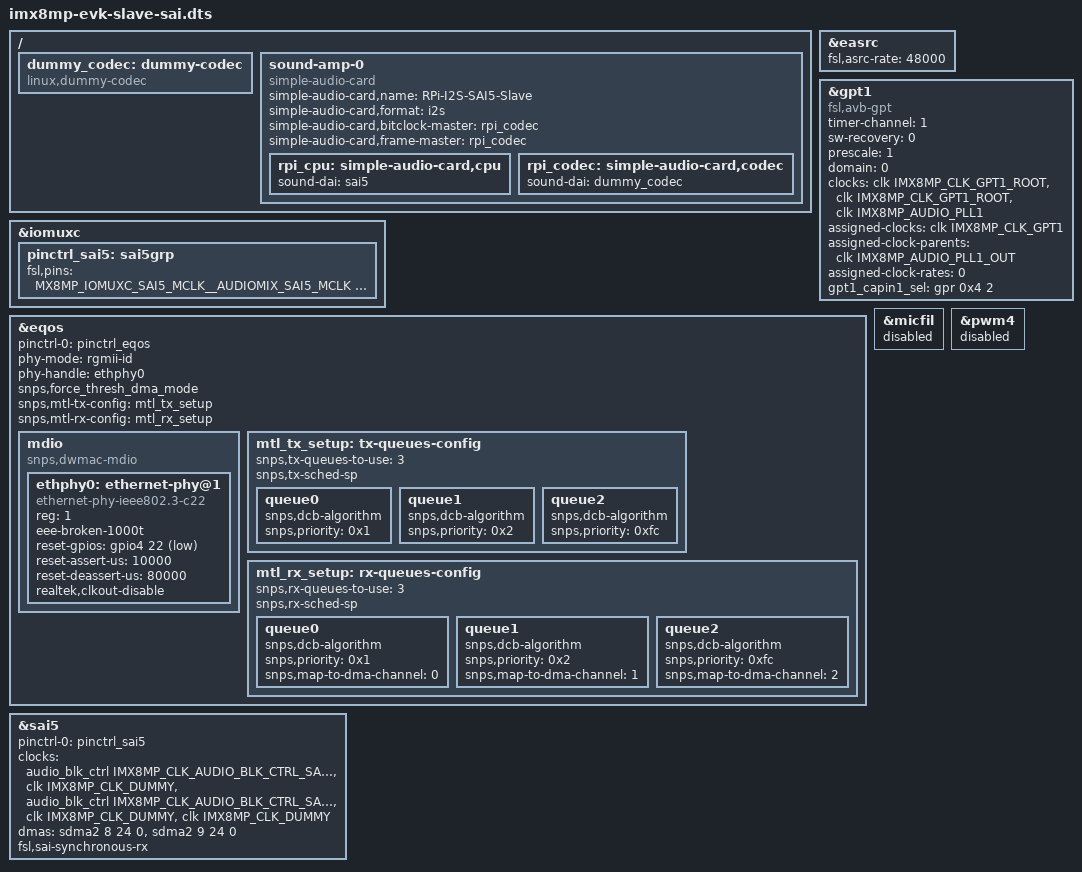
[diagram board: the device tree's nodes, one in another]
// SPDX-License-Identifier: (GPL-2.0+ OR MIT)
/*
 * Copyright 2021 NXP
 */

/dts-v1/;

#include "imx8mp-evk.dts"

/* Enable easrc */
&easrc {
	fsl,asrc-rate  = <48000>;
	status = "okay";
};

/* AVB HW timer*/
&gpt1 {
	compatible = "fsl,avb-gpt";
	timer-channel = <1>; /* Use output compare channel 1*/
	sw-recovery = <0>; /* Use SW recovery mode for STMMAC (eth port 0) */
	prescale = <1>;
	domain = <0>;

	clocks = <&clk IMX8MP_CLK_GPT1_ROOT>,
		 <&clk IMX8MP_CLK_GPT1_ROOT>,
		 <&clk IMX8MP_AUDIO_PLL1>;
	clock-names = "ipg", "per", "audio_pll";

	/* Make the GPT clk root derive from the audio PLL*/
	assigned-clocks = <&clk IMX8MP_CLK_GPT1>;
	assigned-clock-parents = <&clk IMX8MP_AUDIO_PLL1_OUT>;
	assigned-clock-rates = <0>;

	gpt1_capin1_sel = <&gpr 0x4 2>;

	status = "okay";
};

&iomuxc {
	pinctrl_sai5: sai5grp {
		fsl,pins = <
			MX8MP_IOMUXC_SAI5_MCLK__AUDIOMIX_SAI5_MCLK			    0xd6
			MX8MP_IOMUXC_SAI5_RXD0__AUDIOMIX_SAI5_RX_DATA00 		0xd6
			MX8MP_IOMUXC_SAI5_RXC__AUDIOMIX_SAI5_RX_BCLK			0xd6
			MX8MP_IOMUXC_SAI5_RXFS__AUDIOMIX_SAI5_RX_SYNC			0xd6
		>;
	};
};

/ {

	dummy_codec: dummy-codec {
		compatible = "linux,dummy-codec";
		#sound-dai-cells = <0>;
	};

	sound-amp-0 {
		compatible = "simple-audio-card";
		simple-audio-card,name = "RPi-I2S-SAI5-Slave";
		simple-audio-card,format = "i2s";
	/*
	 * Raspberry Pi provides BCLK/LRCLK.
	 * In simple-audio-card bindings, setting bitclock-master/frame-master
	 * to the *codec subnode* makes the CPU DAI a slave (CBP/CFP).
	 */
		simple-audio-card,bitclock-master = <&rpi_codec>;
		simple-audio-card,frame-master = <&rpi_codec>;
		status = "okay";

		rpi_cpu: simple-audio-card,cpu {
			sound-dai = <&sai5>;
		};

		rpi_codec: simple-audio-card,codec {
			sound-dai = <&dummy_codec>;
		};
	};
};

&eqos {
	pinctrl-names = "default";
	pinctrl-0 = <&pinctrl_eqos>;
	phy-mode = "rgmii-id";
	phy-handle = <&ethphy0>;
	snps,force_thresh_dma_mode;
	snps,mtl-tx-config = <&mtl_tx_setup>;
	snps,mtl-rx-config = <&mtl_rx_setup>;
	status = "okay";

	mdio {
		compatible = "snps,dwmac-mdio";
		#address-cells = <1>;
		#size-cells = <0>;

		ethphy0: ethernet-phy@1 {
			compatible = "ethernet-phy-ieee802.3-c22";
			reg = <1>;
			eee-broken-1000t;
			reset-gpios = <&gpio4 22 GPIO_ACTIVE_LOW>;
			reset-assert-us = <10000>;
			reset-deassert-us = <80000>;
			realtek,clkout-disable;
		};
	};

	mtl_tx_setup: tx-queues-config {
		snps,tx-queues-to-use = <3>;
		snps,tx-sched-sp;

		queue0 {
			snps,dcb-algorithm;
			snps,priority = <0x1>;
		};

		queue1 {
			snps,dcb-algorithm;
			snps,priority = <0x2>;
		};

		queue2 {
			snps,dcb-algorithm;
			snps,priority = <0xfc>;
		};
	};

	mtl_rx_setup: rx-queues-config {
		snps,rx-queues-to-use = <3>;
		snps,rx-sched-sp;

		queue0 {
			snps,dcb-algorithm;
			snps,priority = <0x1>;
			snps,map-to-dma-channel = <0>;
		};

		queue1 {
			snps,dcb-algorithm;
			snps,priority = <0x2>;
			snps,map-to-dma-channel = <1>;
		};

		queue2 {
			snps,dcb-algorithm;
			snps,priority = <0xfc>;
			snps,map-to-dma-channel = <2>;
		};
	};
};

&micfil {
	status = "disabled";
};

&pwm4 {
	status = "disabled";
};

&sai5 {
	status = "okay";
	#sound-dai-cells = <0>;
	pinctrl-names = "default";
	pinctrl-0 = <&pinctrl_sai5>;
	clocks = <&audio_blk_ctrl IMX8MP_CLK_AUDIO_BLK_CTRL_SAI5_IPG>, <&clk IMX8MP_CLK_DUMMY>,
		<&audio_blk_ctrl IMX8MP_CLK_AUDIO_BLK_CTRL_SAI5_MCLK1>, <&clk IMX8MP_CLK_DUMMY>,
		<&clk IMX8MP_CLK_DUMMY>;
	clock-names = "bus", "mclk0", "mclk1", "mclk2", "mclk3";
	dmas = <&sdma2 8 24 0>, <&sdma2 9 24 0>;
	dma-names = "rx", "tx";
	fsl,sai-synchronous-rx;
};
